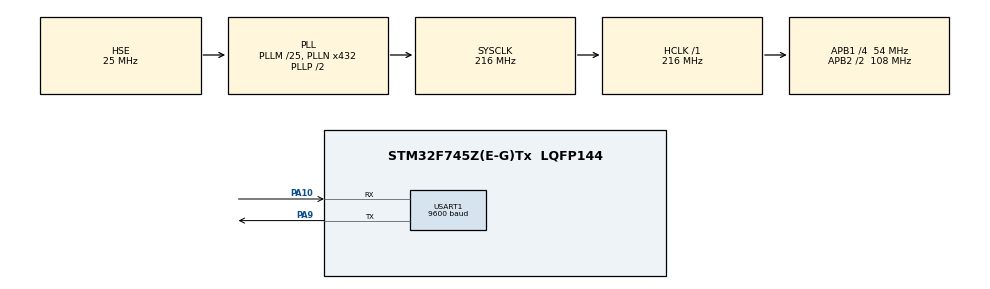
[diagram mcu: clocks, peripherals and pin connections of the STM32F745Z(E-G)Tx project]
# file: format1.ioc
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Mcu.Family=STM32F7
Mcu.Name=STM32F745Z(E-G)Tx
Mcu.Package=LQFP144
NVIC.PriorityGroup=NVIC_PRIORITYGROUP_4
NVIC.USART1_IRQn=true\:0\:0\:false\:false\:true\:true\:true\:true
PA10.Mode=Asynchronous
PA10.Signal=USART1_RX
PA13.Mode=Serial_Wire
PA13.Signal=SYS_JTMS-SWDIO
PA14.Mode=Serial_Wire
PA14.Signal=SYS_JTCK-SWCLK
PA9.Mode=Asynchronous
PA9.Signal=USART1_TX
PH0/OSC_IN.Mode=HSE-External-Oscillator
PH0/OSC_IN.Signal=RCC_OSC_IN
PH1/OSC_OUT.Mode=HSE-External-Oscillator
PH1/OSC_OUT.Signal=RCC_OSC_OUT
ProjectManager.HeapSize=0x200
ProjectManager.StackSize=0x400
ProjectManager.TargetToolchain=STM32CubeIDE
RCC.AHBFreq_Value=216000000
RCC.APB1CLKDivider=RCC_HCLK_DIV4
RCC.APB1Freq_Value=54000000
RCC.APB1TimFreq_Value=108000000
RCC.APB2CLKDivider=RCC_HCLK_DIV2
RCC.APB2Freq_Value=108000000
RCC.APB2TimFreq_Value=216000000
RCC.CortexFreq_Value=216000000
RCC.HCLKFreq_Value=216000000
RCC.HSE_VALUE=25000000
RCC.HSI_VALUE=16000000
RCC.LSE_VALUE=32768
RCC.PLLM=25
RCC.PLLN=432
RCC.PLLSourceVirtual=RCC_PLLSOURCE_HSE
RCC.SYSCLKFreq_VALUE=216000000
RCC.SYSCLKSource=RCC_SYSCLKSOURCE_PLLCLK
RCC.USBFreq_Value=216000000
RCC.VCOOutputFreq_Value=432000000
USART1.BaudRate=9600
USART1.DMADisableonRxErrorParam=ADVFEATURE_DMA_ENABLEONRXERROR
USART1.VirtualMode-Asynchronous=VM_ASYNC
board=custom

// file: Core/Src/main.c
/* USER CODE BEGIN Header */
/**
  ******************************************************************************
  * @file           : main.c
  * @brief          : Main program body
  ******************************************************************************
  * @attention
  *
  * Copyright (c) 2024 STMicroelectronics.
  * All rights reserved.
  *
  * This software is licensed under terms that can be found in the LICENSE file
  * in the root directory of this software component.
  * If no LICENSE file comes with this software, it is provided AS-IS.
  *
  ******************************************************************************
  */
/* USER CODE END Header */
#include "main.h"

/* USER CODE BEGIN Includes */
#include <stdio.h>
#include <string.h>
#include "crcModbus.h"
/* USER CODE END Includes */

/* USER CODE BEGIN PD */

#define SOH 0x01 //start of heading
#define STX 0x02 //start of text
#define ETX 0x03 //end of text
#define EOT 0x04 //end of transmission

/* USER CODE END PD */

UART_HandleTypeDef huart1;

/* USER CODE BEGIN PV */
uint16_t crcPAYLOAD;
uint8_t crc1_PAYLOAD;
uint8_t crc2_PAYLOAD;
uint8_t crc1;
uint8_t crc2;
uint8_t crcControl;
uint8_t sendPACKET;

uint8_t data;
uint8_t RXpayload[256];
uint8_t TXpayload[256];

uint8_t interruptFlag;

uint16_t Intindexx;
uint16_t indexx;
uint16_t indexxPAYLOAD;
uint8_t leng;
uint8_t leng1;
uint16_t indexETX;
uint8_t sending;

/* USER CODE END PV */

void SystemClock_Config(void);
static void MX_GPIO_Init(void);
static void MX_USART1_UART_Init(void);
/* USER CODE BEGIN PFP */

void clearPAYLOAD(void)
{
	for (int i = 0; i <= indexxPAYLOAD; i++)
	{
		RXpayload[i] = 0;
	}
	indexxPAYLOAD = 0;
}
/* USER CODE END PFP */

/* USER CODE BEGIN 0 */
void HAL_UART_RxCpltCallback(UART_HandleTypeDef *huart)
{

		if(indexx==0 && data==SOH) //is first index SOH?
		{
			indexx++;
		}
		else if(indexx==1)//if first index is SOH then second index is data lenght.
		{
			leng=data;
			indexETX=3+leng; //After this, the location of crc, etx and eot is determined according to the byte that gives the data length.
			indexx++;

			if(leng==0)
			{
				indexx=0;
			}
		}
		else if(indexx==2 && data==STX)//check the beginning of the text.
		{
			indexx++;
			clearPAYLOAD(); //if data format is true then clear payload and new receiving data is your real data BUT not finished yet.
		}
		else if(indexx>2 && indexx<indexETX)//Store data until the ETX byte arrives.
		{
			RXpayload[indexxPAYLOAD]=data;
			indexxPAYLOAD++;
			indexx++;
		}
		else if(indexx==indexETX && data==ETX)//After the real data arrives, check if the etx data has arrived, if so, increase the index by one.
		{
			indexx++;
		}
		else if(indexx==indexETX+1)//The accuracy of the message coming after etx is verified according to the crc modbus-16 protocol.
		{
			crc1=data;
			indexx++;
		}
		else if (indexx == indexETX + 2)
		{
			crc2 = data;
			indexx++;
		}
		else if (indexx == indexETX + 3&& data==EOT)
		{
			crcPAYLOAD = CRC16_Modbus(RXpayload, leng);
			crc1_PAYLOAD = crcPAYLOAD >> 8;
			crc2_PAYLOAD = crcPAYLOAD;
			if (crc1 == crc1_PAYLOAD && crc2 == crc2_PAYLOAD)
			{
				sendPACKET=1;
			}
			indexx=0;
		}
		else
		{
			indexx=0;
		}

		 HAL_UART_Receive_IT(&huart1, &data, 1); //	 We get data byte by byte so we don't lose as much data as possible.

}

/* USER CODE END 0 */

int main(void)
{

  /* MCU Configuration--------------------------------------------------------*/

  /* Reset of all peripherals, Initializes the Flash interface and the Systick. */
  HAL_Init();

  /* Configure the system clock */
  SystemClock_Config();

  /* Initialize all configured peripherals */
  MX_GPIO_Init();
  MX_USART1_UART_Init();
  /* USER CODE BEGIN 2 */
  HAL_UART_Receive_IT(&huart1, &data, 1);// first time we need to start UART_IT
  /* USER CODE END 2 */

  /* Infinite loop */
  /* USER CODE BEGIN WHILE */
  while (1)
  {
	  if(sendPACKET==1) //if DATA is OK then SEND DATA.
	  {
		  leng1=leng;
		  for(int i =0;i<leng1;i++)
		  {
		  TXpayload[i]=RXpayload[i];
		  }
		  HAL_UART_Transmit(&huart1, TXpayload,  leng1, 500);
		  sendPACKET=0;
	  }

    /* USER CODE END WHILE */

  }
}

void SystemClock_Config(void)
{
  RCC_OscInitTypeDef RCC_OscInitStruct = {0};
  RCC_ClkInitTypeDef RCC_ClkInitStruct = {0};

  /** Configure the main internal regulator output voltage
  */
  __HAL_RCC_PWR_CLK_ENABLE();
  __HAL_PWR_VOLTAGESCALING_CONFIG(PWR_REGULATOR_VOLTAGE_SCALE1);

  /** Initializes the RCC Oscillators according to the specified parameters
  * in the RCC_OscInitTypeDef structure.
  */
  RCC_OscInitStruct.OscillatorType = RCC_OSCILLATORTYPE_HSE;
  RCC_OscInitStruct.HSEState = RCC_HSE_ON;
  RCC_OscInitStruct.PLL.PLLState = RCC_PLL_ON;
  RCC_OscInitStruct.PLL.PLLSource = RCC_PLLSOURCE_HSE;
  RCC_OscInitStruct.PLL.PLLM = 25;
  RCC_OscInitStruct.PLL.PLLN = 432;
  RCC_OscInitStruct.PLL.PLLP = RCC_PLLP_DIV2;
  RCC_OscInitStruct.PLL.PLLQ = 2;
  if (HAL_RCC_OscConfig(&RCC_OscInitStruct) != HAL_OK)
  {
    Error_Handler();
  }

  /** Activate the Over-Drive mode
  */
  if (HAL_PWREx_EnableOverDrive() != HAL_OK)
  {
    Error_Handler();
  }

  /** Initializes the CPU, AHB and APB buses clocks
  */
  RCC_ClkInitStruct.ClockType = RCC_CLOCKTYPE_HCLK|RCC_CLOCKTYPE_SYSCLK
                              |RCC_CLOCKTYPE_PCLK1|RCC_CLOCKTYPE_PCLK2;
  RCC_ClkInitStruct.SYSCLKSource = RCC_SYSCLKSOURCE_PLLCLK;
  RCC_ClkInitStruct.AHBCLKDivider = RCC_SYSCLK_DIV1;
  RCC_ClkInitStruct.APB1CLKDivider = RCC_HCLK_DIV4;
  RCC_ClkInitStruct.APB2CLKDivider = RCC_HCLK_DIV2;

  if (HAL_RCC_ClockConfig(&RCC_ClkInitStruct, FLASH_LATENCY_7) != HAL_OK)
  {
    Error_Handler();
  }
}

static void MX_USART1_UART_Init(void)
{

  huart1.Instance = USART1;
  huart1.Init.BaudRate = 9600;
  huart1.Init.WordLength = UART_WORDLENGTH_8B;
  huart1.Init.StopBits = UART_STOPBITS_1;
  huart1.Init.Parity = UART_PARITY_NONE;
  huart1.Init.Mode = UART_MODE_TX_RX;
  huart1.Init.HwFlowCtl = UART_HWCONTROL_NONE;
  huart1.Init.OverSampling = UART_OVERSAMPLING_16;
  huart1.Init.OneBitSampling = UART_ONE_BIT_SAMPLE_DISABLE;
  huart1.AdvancedInit.AdvFeatureInit = UART_ADVFEATURE_NO_INIT;
  if (HAL_UART_Init(&huart1) != HAL_OK)
  {
    Error_Handler();
  }

}

static void MX_GPIO_Init(void)
{

  /* GPIO Ports Clock Enable */
  __HAL_RCC_GPIOH_CLK_ENABLE();
  __HAL_RCC_GPIOA_CLK_ENABLE();

}

void Error_Handler(void)
{
  __disable_irq();
  while (1)
  {
  }
}
